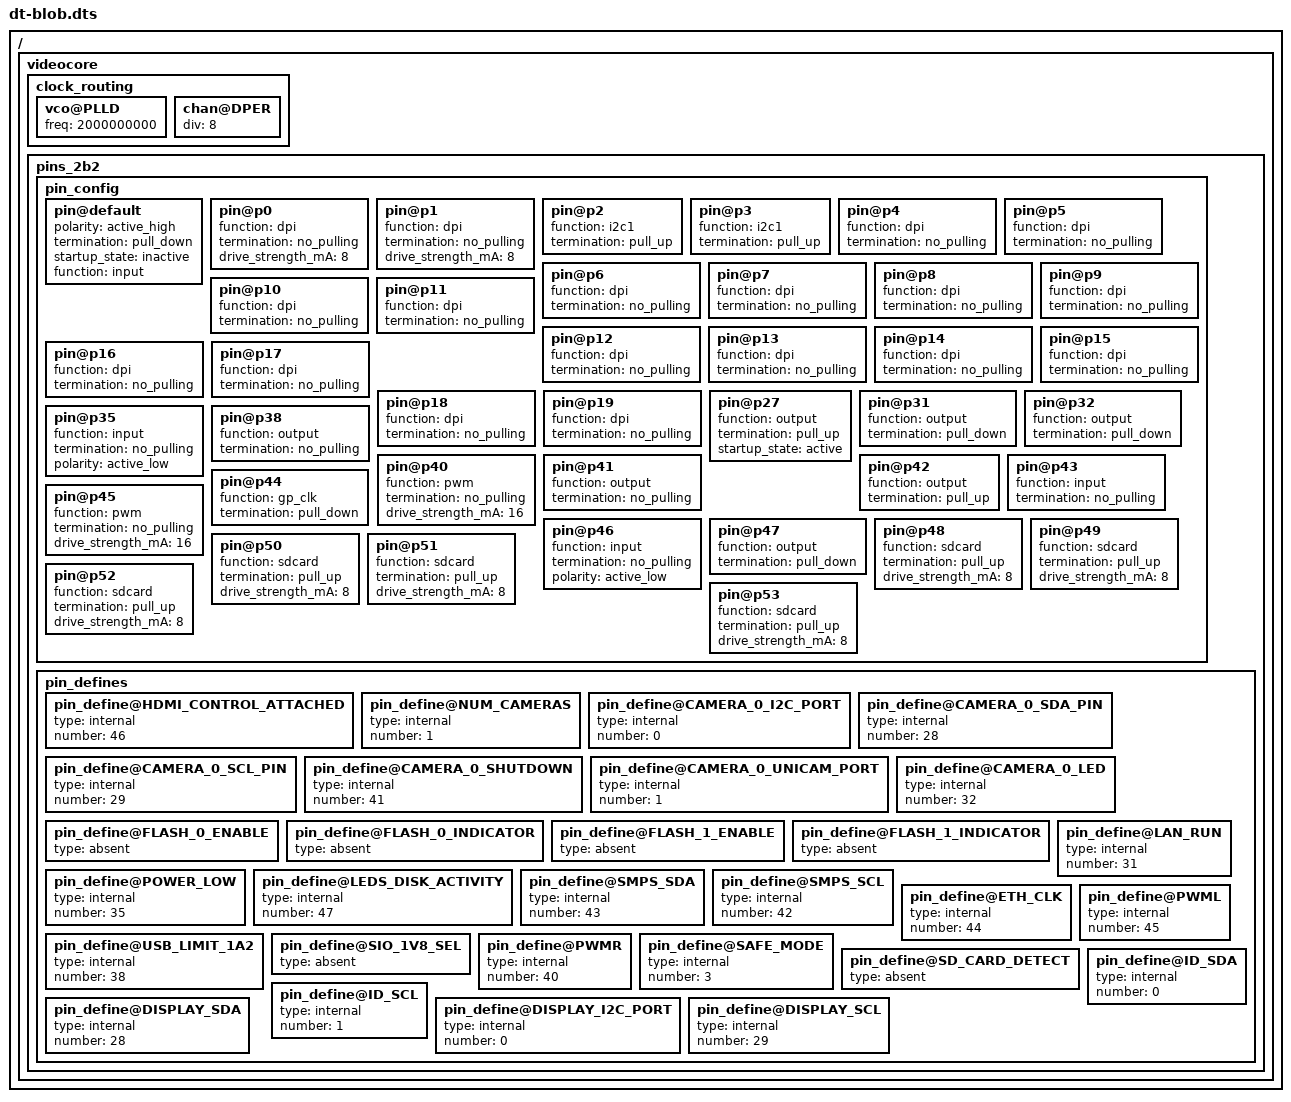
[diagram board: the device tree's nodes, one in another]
/dts-v1/;

/ {
   videocore {
      clock_routing {
        vco@PLLD { freq = <2000000000>; };
        chan@DPER { div = <8>; }; // APER will be 500MHz
      }; // clock routing

      pins_2b2 { // Pi 2 Model B rev 1.1
         pin_config {
            pin@default {
               polarity = "active_high";
               termination = "pull_down";
               startup_state = "inactive";
               function = "input";
            }; // pin

            pin@p0  { function = "dpi";    termination = "no_pulling"; drive_strength_mA = < 8 >; };	// PCLK-OUT
            pin@p1  { function = "dpi";    termination = "no_pulling"; drive_strength_mA = < 8 >; };	// DE-OUT

            pin@p2  { function = "i2c1";   termination = "pull_up";    }; // I2C 1 SDA
            pin@p3  { function = "i2c1";   termination = "pull_up";    }; // I2C 1 SCL

            pin@p4  { function = "dpi";    termination = "no_pulling"; };	// B3-Out
            pin@p5  { function = "dpi";    termination = "no_pulling"; };	// B4-Out
            pin@p6  { function = "dpi";    termination = "no_pulling"; };	// B5-Out
            pin@p7  { function = "dpi";    termination = "no_pulling"; };	// B6-Out
            pin@p8  { function = "dpi";    termination = "no_pulling"; };	// B7-Out

            pin@p9  { function = "dpi";    termination = "no_pulling"; };	// G2-Out
            pin@p10 { function = "dpi";    termination = "no_pulling"; };	// G3-Out
            pin@p11 { function = "dpi";    termination = "no_pulling"; };	// G4-Out
            pin@p12 { function = "dpi";    termination = "no_pulling"; };	// G5-Out
            pin@p13 { function = "dpi";    termination = "no_pulling"; };	// G6-Out
            pin@p14 { function = "dpi";    termination = "no_pulling"; };	// G7-Out

            pin@p15 { function = "dpi";    termination = "no_pulling"; };	// R3-Out
            pin@p16 { function = "dpi";    termination = "no_pulling"; };	// R4-Out
            pin@p17 { function = "dpi";    termination = "no_pulling"; };	// R5-Out
            pin@p18 { function = "dpi";    termination = "no_pulling"; };	// R6-Out
            pin@p19 { function = "dpi";    termination = "no_pulling"; };	// R7-Out

			// Pin 20..26 are the Jog Shuttle controls, they are all inputs, which is covered by the pin@default case
			// p20 = Right button
			// p21 = Left button
			// p22 = Rot1			(Rot1 ^ Rot2) != 0 => Right, (Rot1 ^ Rot2) == 0 => Left if an edge was detected
			// p23 = Center button
			// p24 = Rot2
			// p25 = Down button
			// p26 = Left button

            pin@p27 { function = "output"; termination = "pull_up"; startup_state = "active"; };	// LCD Backlight enable, active at boot

			// From here on it is identical to Jessie's defaults:

            // The firmware changes I2C pin functions on the fly, returning them to inputs when done. But pins 28&29 are
            // not used on a 1.1 Pi2, so the I2C0 function ends up multiply mapped (bad). therefore don't statically map.
            // pin@p28 { function = "i2c0";   termination = "pull_up";    }; // I2C 0 SDA
            // pin@p29 { function = "i2c0";   termination = "pull_up";    }; // I2C 0 SCL
            pin@p31 { function = "output"; termination = "pull_down"; }; // LAN_RUN
            pin@p32 { function = "output"; termination = "pull_down"; }; // Camera LED
            pin@p35 { function = "input";  termination = "no_pulling"; polarity = "active_low"; }; // Power low
            pin@p38 { function = "output"; termination = "no_pulling";    }; // USB current limit (0=600mA, 1=1200mA)
            pin@p40 { function = "pwm";    termination = "no_pulling"; drive_strength_mA = < 16 >; }; // Right audio
            pin@p41 { function = "output"; termination = "no_pulling";    }; // Camera shutdown
            // Communicate with the SMPS by "bit-bashing" the I2C protocol on GPIOs 42 and 43
            pin@p42 { function = "output"; termination = "pull_up";    }; // SMPS_SCL
            pin@p43 { function = "input";  termination = "no_pulling";    }; // SMPS_SDA
            pin@p44 { function = "gp_clk"; termination = "pull_down"; }; // ETH_CLK - Ethernet 25MHz output
            pin@p45 { function = "pwm";    termination = "no_pulling"; drive_strength_mA = < 16 >; }; // Left audio

            pin@p46 { function = "input";  termination = "no_pulling"; polarity = "active_low"; }; // HDMI hotplug detect (goes to pin 6 of IC1)
            pin@p47 { function = "output"; termination = "pull_down"; }; // activity LED
            pin@p48 { function = "sdcard"; termination = "pull_up";    drive_strength_mA = < 8 >; }; // SD CLK
            pin@p49 { function = "sdcard"; termination = "pull_up";    drive_strength_mA = < 8 >; }; // SD CMD
            pin@p50 { function = "sdcard"; termination = "pull_up";    drive_strength_mA = < 8 >; }; // SD D0
            pin@p51 { function = "sdcard"; termination = "pull_up";    drive_strength_mA = < 8 >; }; // SD D1
            pin@p52 { function = "sdcard"; termination = "pull_up";    drive_strength_mA = < 8 >; }; // SD D2
            pin@p53 { function = "sdcard"; termination = "pull_up";    drive_strength_mA = < 8 >; }; // SD D3
         }; // pin_config

         pin_defines {
            pin_define@HDMI_CONTROL_ATTACHED { type = "internal"; number = <46>; };

            pin_define@NUM_CAMERAS { type = "internal"; number = <1>; };
            pin_define@CAMERA_0_I2C_PORT { type = "internal"; number = <0>; };
            pin_define@CAMERA_0_SDA_PIN { type = "internal"; number = <28>; };
            pin_define@CAMERA_0_SCL_PIN { type = "internal"; number = <29>; };
            pin_define@CAMERA_0_SHUTDOWN { type = "internal"; number = <41>; };
            pin_define@CAMERA_0_UNICAM_PORT { type = "internal"; number = <1>; };
            pin_define@CAMERA_0_LED { type = "internal"; number = <32>; };

            pin_define@FLASH_0_ENABLE { type = "absent"; };
            pin_define@FLASH_0_INDICATOR { type = "absent"; };
            pin_define@FLASH_1_ENABLE { type = "absent"; };
            pin_define@FLASH_1_INDICATOR { type = "absent"; };

            pin_define@POWER_LOW { type = "internal"; number = <35>; };
            pin_define@LEDS_DISK_ACTIVITY { type = "internal"; number = <47>; };
            pin_define@LAN_RUN { type = "internal"; number = <31>; };
            pin_define@SMPS_SDA { type = "internal"; number = <43>; };
            pin_define@SMPS_SCL { type = "internal"; number = <42>; };
            pin_define@ETH_CLK { type = "internal"; number = <44>; };
            pin_define@USB_LIMIT_1A2 { type = "internal"; number = <38>; };
            pin_define@SIO_1V8_SEL { type = "absent"; };
            pin_define@PWML { type = "internal"; number = <45>; };
            pin_define@PWMR { type = "internal"; number = <40>; };
            pin_define@SAFE_MODE { type = "internal"; number = <3>; };
            pin_define@SD_CARD_DETECT { type = "absent"; };
            pin_define@ID_SDA { type = "internal"; number = <0>; };
            pin_define@ID_SCL { type = "internal"; number = <1>; };
            pin_define@DISPLAY_I2C_PORT { type = "internal"; number = <0>; };
            pin_define@DISPLAY_SDA { type = "internal"; number = <28>; };
            pin_define@DISPLAY_SCL { type = "internal"; number = <29>; };
         }; // pin_defines
      }; // pins

   };
};
